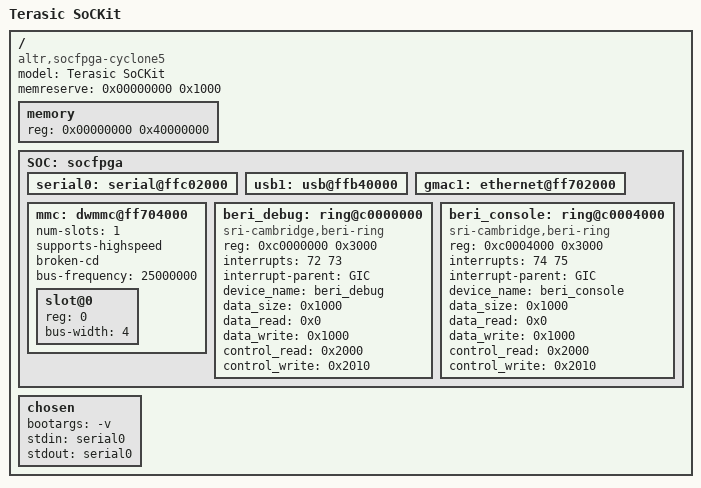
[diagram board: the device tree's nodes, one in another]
/*-
 * Copyright (c) 2014 Ruslan Bukin <br@bsdpad.com>
 * All rights reserved.
 *
 * This software was developed by SRI International and the University of
 * Cambridge Computer Laboratory under DARPA/AFRL contract (FA8750-10-C-0237)
 * ("CTSRD"), as part of the DARPA CRASH research programme.
 *
 * Redistribution and use in source and binary forms, with or without
 * modification, are permitted provided that the following conditions
 * are met:
 * 1. Redistributions of source code must retain the above copyright
 *    notice, this list of conditions and the following disclaimer.
 * 2. Redistributions in binary form must reproduce the above copyright
 *    notice, this list of conditions and the following disclaimer in the
 *    documentation and/or other materials provided with the distribution.
 *
 * THIS SOFTWARE IS PROVIDED BY THE AUTHOR AND CONTRIBUTORS ``AS IS'' AND
 * ANY EXPRESS OR IMPLIED WARRANTIES, INCLUDING, BUT NOT LIMITED TO, THE
 * IMPLIED WARRANTIES OF MERCHANTABILITY AND FITNESS FOR A PARTICULAR PURPOSE
 * ARE DISCLAIMED.  IN NO EVENT SHALL THE AUTHOR OR CONTRIBUTORS BE LIABLE
 * FOR ANY DIRECT, INDIRECT, INCIDENTAL, SPECIAL, EXEMPLARY, OR CONSEQUENTIAL
 * DAMAGES (INCLUDING, BUT NOT LIMITED TO, PROCUREMENT OF SUBSTITUTE GOODS
 * OR SERVICES; LOSS OF USE, DATA, OR PROFITS; OR BUSINESS INTERRUPTION)
 * HOWEVER CAUSED AND ON ANY THEORY OF LIABILITY, WHETHER IN CONTRACT, STRICT
 * LIABILITY, OR TORT (INCLUDING NEGLIGENCE OR OTHERWISE) ARISING IN ANY WAY
 * OUT OF THE USE OF THIS SOFTWARE, EVEN IF ADVISED OF THE POSSIBILITY OF
 * SUCH DAMAGE.
 *
 * $FreeBSD$
 */

/dts-v1/;

/include/ "socfpga.dtsi"

/ {
	model = "Terasic SoCKit";
	compatible = "altr,socfpga-cyclone5", "altr,socfpga";

	/* Reserve first page for secondary CPU trampoline code */
	memreserve = < 0x00000000 0x1000 >;

	memory {
		device_type = "memory";
		reg = < 0x00000000 0x40000000 >;	/* 1G RAM */
	};

	SOC: socfpga {
		serial0: serial@ffc02000 {
			status = "okay";
		};

		usb1: usb@ffb40000 {
			status = "okay";
		};

		gmac1: ethernet@ff702000 {
			status = "okay";
		};

		mmc: dwmmc@ff704000 {
			status = "okay";
			num-slots = <1>;
			supports-highspeed;
			broken-cd;
			bus-frequency = <25000000>;

			slot@0 {
				reg = <0>;
				bus-width = <4>;
			};	
		};

		beri_debug: ring@c0000000 {
			compatible = "sri-cambridge,beri-ring";
			reg = <0xc0000000 0x3000>;
			interrupts = < 72 73 >;
			interrupt-parent = <&GIC>;
			device_name = "beri_debug";
			data_size = <0x1000>;
			data_read = <0x0>;
			data_write = <0x1000>;
			control_read = <0x2000>;
			control_write = <0x2010>;
			status = "okay";
		};

		beri_console: ring@c0004000 {
			compatible = "sri-cambridge,beri-ring";
			reg = <0xc0004000 0x3000>;
			interrupts = < 74 75 >;
			interrupt-parent = <&GIC>;
			device_name = "beri_console";
			data_size = <0x1000>;
			data_read = <0x0>;
			data_write = <0x1000>;
			control_read = <0x2000>;
			control_write = <0x2010>;
			status = "okay";
		};
	};

	chosen {
		bootargs = "-v";
		stdin = "serial0";
		stdout = "serial0";
	};
};
